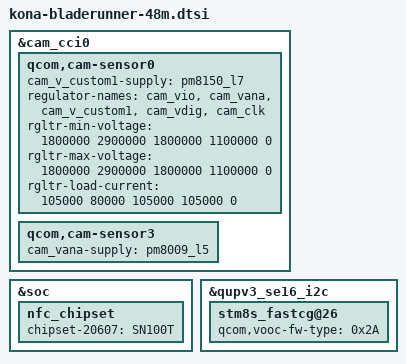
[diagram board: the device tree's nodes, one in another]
// camera/kona-camera-sensor-mtp.dtsi
&cam_cci0 {

    //s5kgw1
    qcom,cam-sensor0 {
        cam_v_custom1-supply = <&pm8150_l7>;
        regulator-names = "cam_vio", "cam_vana",  "cam_v_custom1",  "cam_vdig",
			"cam_clk";
        rgltr-min-voltage = <1800000  2900000  1800000  1100000 0>;
		rgltr-max-voltage = <1800000  2900000  1800000  1100000 0>;
		rgltr-load-current = <105000 80000 105000 105000 0>;
    };

    //tele
    qcom,cam-sensor3 {
        cam_vana-supply = <&pm8009_l5>;
    };
};

// kona-mtp.dtsi
&soc {
	//#ifdef OPLUS_FEATURE_CONNFCSOFT
	nfc_chipset {
		/delete-property/ chipset-19706;
		/delete-property/ chipset-19795;
        chipset-20607 = "SN100T";
	};
	//#endif /* OPLUS_FEATURE_CONNFCSOFT */
};

&qupv3_se16_i2c {
    stm8s_fastcg@26 {
        qcom,vooc-fw-type = <0x2A>;//6A
    };
};
